# ATSAMA5D31 register map
Vendor: Microchip Technology; Series: SAMA5D3; File version: 0
Registers are 32-bit, read-write, reset 0x0 unless marked. A register's access mark holds for its fields unless they carry their own. Offsets are from the block's base; [hi:lo] are bit positions; {n}, {i} and the like mark numbered series.

## SHDWC — Shutdown Controller
Base 0xFFFFFE10
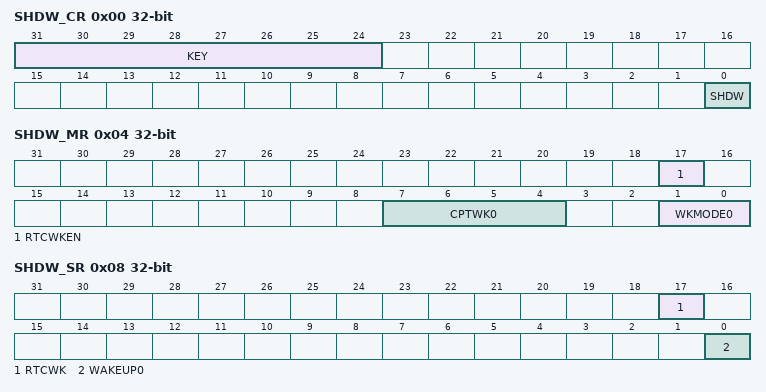
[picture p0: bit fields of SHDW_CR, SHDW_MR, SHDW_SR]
0x00 SHDW_CR wo — Shutdown Control Register
  [31:24] KEY — Password
    165=PASSWD (Writing any other value in this field aborts the write operation.)
  [0] SHDW — Shutdown Command
0x04 SHDW_MR — Shutdown Mode Register
  [17] RTCWKEN — Real-time Clock Wake-up Enable
  [7:4] CPTWK0 — Debounce Counter on Wake-up 0
  [1:0] WKMODE0 — Wake-up Mode 0
    0=NO_DETECTION (No detection is performed on the wake-up input); 1=RISING_EDGE (Low to high transition triggers the detection process); 2=FALLING_EDGE (High to low level transition triggers the detection process); 3=ANY_EDGE (Any edge on the wake-up input triggers the detection process)
0x08 SHDW_SR ro — Shutdown Status Register
  [17] RTCWK — Real-time Clock Wake-up
  [0] WAKEUP0 — Wake-up 0 Status

## SMD — Software Modem Device
Base 0x00400000
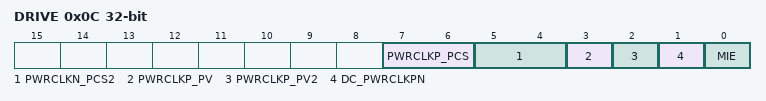
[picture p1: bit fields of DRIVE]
0x0C DRIVE — SMD Drive Register
  [7:6] PWRCLKP_PCS — PWRCLKP Pin Control Select
  [5:4] PWRCLKN_PCS2 — PWRCLKN Pin Control Select
  [3] PWRCLKP_PV — PWRCLKP Pin Value
  [2] PWRCLKP_PV2 — PWRCLKP Pin Value
  [1] DC_PWRCLKPN — Direct Control of PWRCLKP, PWRCLKN Pins Enable
  [0] MIE — MADCVS Interrupt Enable

## SPI0 — Serial Peripheral Interface
Base 0xF0004000; register names take the prefix SPI_
Same registers: SPI1 0xF8008000
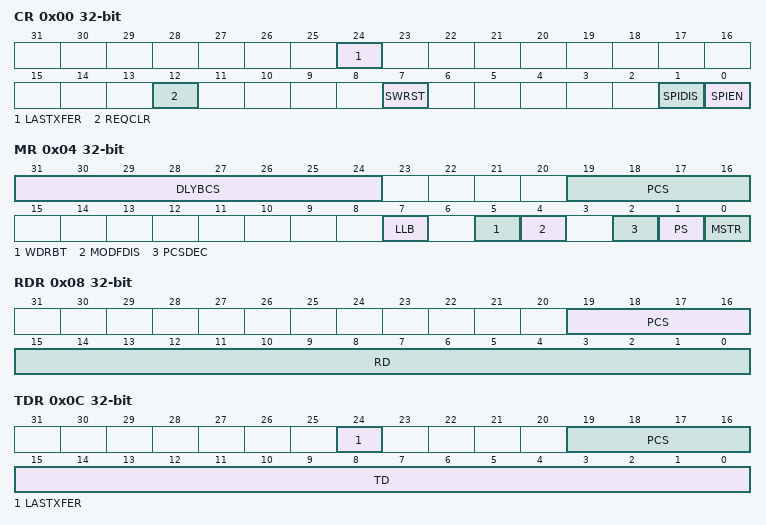
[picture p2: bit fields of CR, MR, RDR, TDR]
0x00 CR wo — Control Register
  [24] LASTXFER — Last Transfer
  [12] REQCLR — Request to Clear the Comparison Trigger
  [7] SWRST — SPI Software Reset
  [1] SPIDIS — SPI Disable
  [0] SPIEN — SPI Enable
0x04 MR — Mode Register
  [31:24] DLYBCS — Delay Between Chip Selects
  [19:16] PCS — Peripheral Chip Select
  [7] LLB — Local Loopback Enable
  [5] WDRBT — Wait Data Read Before Transfer
  [4] MODFDIS — Mode Fault Detection
  [2] PCSDEC — Chip Select Decode
  [1] PS — Peripheral Select
  [0] MSTR — Master/Slave Mode
0x08 RDR ro — Receive Data Register
  [19:16] PCS — Peripheral Chip Select
  [15:0] RD — Receive Data
0x0C TDR wo — Transmit Data Register
  [24] LASTXFER — Last Transfer
  [19:16] PCS — Peripheral Chip Select
  [15:0] TD — Transmit Data
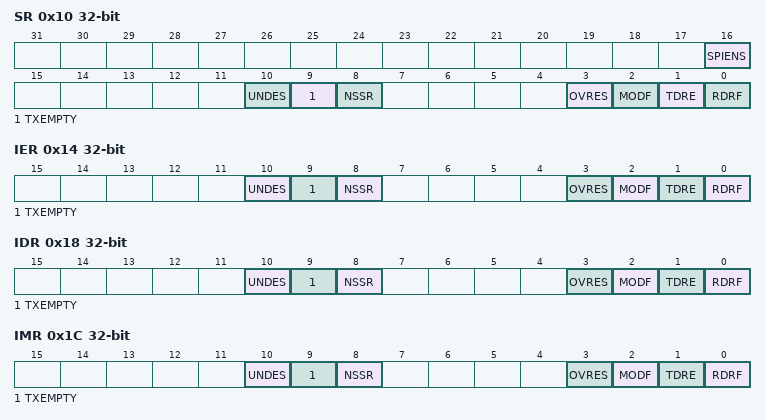
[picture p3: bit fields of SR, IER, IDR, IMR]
0x10 SR ro — Status Register
  [16] SPIENS — SPI Enable Status
  [10] UNDES — Underrun Error Status (Slave mode only) (cleared on read)
  [9] TXEMPTY — Transmission Registers Empty (cleared by writing SPI_TDR)
  [8] NSSR — NSS Rising (cleared on read)
  [3] OVRES — Overrun Error Status (cleared on read)
  [2] MODF — Mode Fault Error (cleared on read)
  [1] TDRE — Transmit Data Register Empty (cleared by writing SPI_TDR)
  [0] RDRF — Receive Data Register Full (cleared by reading SPI_RDR)
0x14 IER wo — Interrupt Enable Register
  [10] UNDES — Underrun Error Interrupt Enable
  [9] TXEMPTY — Transmission Registers Empty Enable
  [8] NSSR — NSS Rising Interrupt Enable
  [3] OVRES — Overrun Error Interrupt Enable
  [2] MODF — Mode Fault Error Interrupt Enable
  [1] TDRE — SPI Transmit Data Register Empty Interrupt Enable
  [0] RDRF — Receive Data Register Full Interrupt Enable
0x18 IDR wo — Interrupt Disable Register
  [10] UNDES — Underrun Error Interrupt Disable
  [9] TXEMPTY — Transmission Registers Empty Disable
  [8] NSSR — NSS Rising Interrupt Disable
  [3] OVRES — Overrun Error Interrupt Disable
  [2] MODF — Mode Fault Error Interrupt Disable
  [1] TDRE — SPI Transmit Data Register Empty Interrupt Disable
  [0] RDRF — Receive Data Register Full Interrupt Disable
0x1C IMR ro — Interrupt Mask Register
  [10] UNDES — Underrun Error Interrupt Mask
  [9] TXEMPTY — Transmission Registers Empty Mask
  [8] NSSR — NSS Rising Interrupt Mask
  [3] OVRES — Overrun Error Interrupt Mask
  [2] MODF — Mode Fault Error Interrupt Mask
  [1] TDRE — SPI Transmit Data Register Empty Interrupt Mask
  [0] RDRF — Receive Data Register Full Interrupt Mask
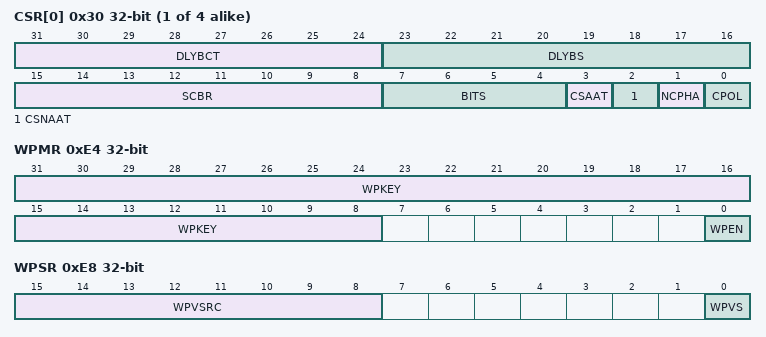
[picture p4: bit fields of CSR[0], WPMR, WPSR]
{0x30+4i} CSR[{i}] (i=0..3) — Chip Select Register (CS_number = 0)
  [31:24] DLYBCT — Delay Between Consecutive Transfers
  [23:16] DLYBS — Delay Before SPCK
  [15:8] SCBR — Serial Clock Bit Rate
  [7:4] BITS — Bits Per Transfer
    {v}=_{v+8}_BIT ({v+8} bits for transfer) (v=0..8)
  [3] CSAAT — Chip Select Active After Transfer
  [2] CSNAAT — Chip Select Not Active After Transfer (Ignored if CSAAT = 1)
  [1] NCPHA — Clock Phase
  [0] CPOL — Clock Polarity
0xE4 WPMR — Write Protection Mode Register
  [31:8] WPKEY — Write Protection Key
    0x535049=PASSWD (Writing any other value in this field aborts the write operation of the WPEN bit.Always reads as 0.)
  [0] WPEN — Write Protection Enable
0xE8 WPSR ro — Write Protection Status Register
  [15:8] WPVSRC — Write Protection Violation Source
  [0] WPVS — Write Protection Violation Status
